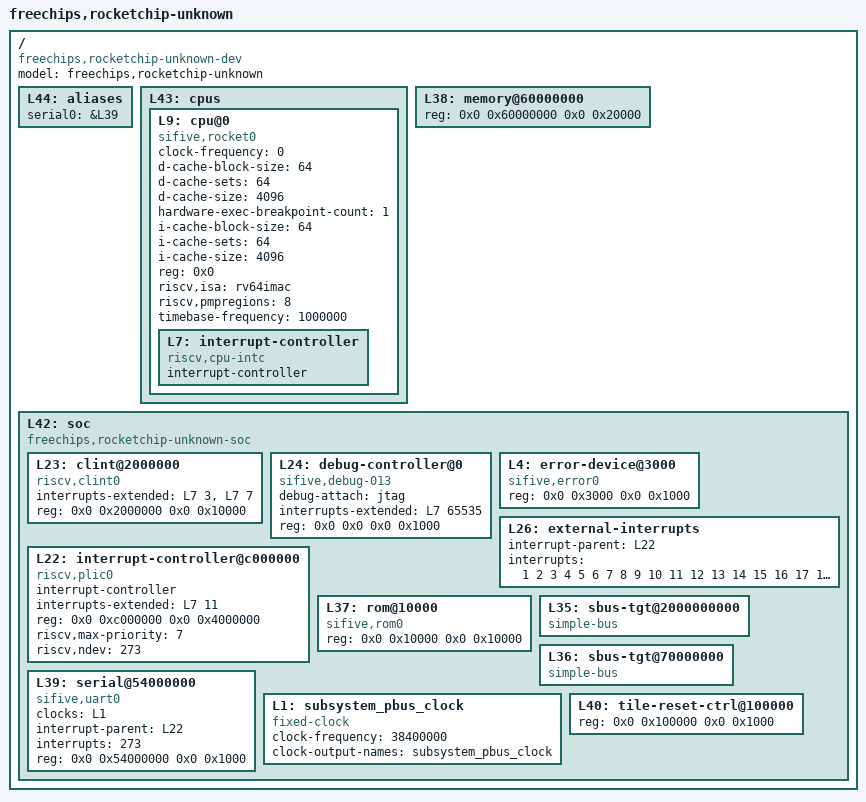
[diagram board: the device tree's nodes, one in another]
/dts-v1/;

/ {
    #address-cells = <2>;
    #size-cells = <2>;
    compatible = "freechips,rocketchip-unknown-dev";
    model = "freechips,rocketchip-unknown";
    L44: aliases {
        serial0 = &L39;
    };
    L43: cpus {
        #address-cells = <1>;
        #size-cells = <0>;
        L9: cpu@0 {
            clock-frequency = <0>;
            compatible = "sifive,rocket0", "riscv";
            d-cache-block-size = <64>;
            d-cache-sets = <64>;
            d-cache-size = <4096>;
            device_type = "cpu";
            hardware-exec-breakpoint-count = <1>;
            i-cache-block-size = <64>;
            i-cache-sets = <64>;
            i-cache-size = <4096>;
            reg = <0x0>;
            riscv,isa = "rv64imac";
            riscv,pmpregions = <8>;
            status = "okay";
            timebase-frequency = <1000000>;
            L7: interrupt-controller {
                #interrupt-cells = <1>;
                compatible = "riscv,cpu-intc";
                interrupt-controller;
            };
        };
    };
    L38: memory@60000000 {
        device_type = "memory";
        reg = <0x0 0x60000000 0x0 0x20000>;
    };
    L42: soc {
        #address-cells = <2>;
        #size-cells = <2>;
        compatible = "freechips,rocketchip-unknown-soc", "simple-bus";
        ranges;
        L23: clint@2000000 {
            compatible = "riscv,clint0";
            interrupts-extended = <&L7 3 &L7 7>;
            reg = <0x0 0x2000000 0x0 0x10000>;
            reg-names = "control";
        };
        L24: debug-controller@0 {
            compatible = "sifive,debug-013", "riscv,debug-013";
            debug-attach = "jtag";
            interrupts-extended = <&L7 65535>;
            reg = <0x0 0x0 0x0 0x1000>;
            reg-names = "control";
        };
        L4: error-device@3000 {
            compatible = "sifive,error0";
            reg = <0x0 0x3000 0x0 0x1000>;
        };
        L26: external-interrupts {
            interrupt-parent = <&L22>;
            interrupts = <1 2 3 4 5 6 7 8 9 10 11 12 13 14 15 16 17 18 19 20 21 22 23 24 25 26 27 28 29 30 31 32 33 34 35 36 37 38 39 40 41 42 43 44 45 46 47 48 49 50 51 52 53 54 55 56 57 58 59 60 61 62 63 64 65 66 67 68 69 70 71 72 73 74 75 76 77 78 79 80 81 82 83 84 85 86 87 88 89 90 91 92 93 94 95 96 97 98 99 100 101 102 103 104 105 106 107 108 109 110 111 112 113 114 115 116 117 118 119 120 121 122 123 124 125 126 127 128 129 130 131 132 133 134 135 136 137 138 139 140 141 142 143 144 145 146 147 148 149 150 151 152 153 154 155 156 157 158 159 160 161 162 163 164 165 166 167 168 169 170 171 172 173 174 175 176 177 178 179 180 181 182 183 184 185 186 187 188 189 190 191 192 193 194 195 196 197 198 199 200 201 202 203 204 205 206 207 208 209 210 211 212 213 214 215 216 217 218 219 220 221 222 223 224 225 226 227 228 229 230 231 232 233 234 235 236 237 238 239 240 241 242 243 244 245 246 247 248 249 250 251 252 253 254 255 256 257 258 259 260 261 262 263 264 265 266 267 268 269 270 271 272>;
        };
        L22: interrupt-controller@c000000 {
            #interrupt-cells = <1>;
            compatible = "riscv,plic0";
            interrupt-controller;
            interrupts-extended = <&L7 11>;
            reg = <0x0 0xc000000 0x0 0x4000000>;
            reg-names = "control";
            riscv,max-priority = <7>;
            riscv,ndev = <273>;
        };
        L37: rom@10000 {
            compatible = "sifive,rom0";
            reg = <0x0 0x10000 0x0 0x10000>;
            reg-names = "mem";
        };
        L35: sbus-tgt@2000000000 {
            #address-cells = <2>;
            #size-cells = <2>;
            compatible = "simple-bus";
            ranges = <0x20 0x0 0x20 0x0 0x30 0x0>;
        };
        L36: sbus-tgt@70000000 {
            #address-cells = <2>;
            #size-cells = <2>;
            compatible = "simple-bus";
            ranges = <0x0 0x70000000 0x0 0x70000000 0xf 0x90000000>;
        };
        L39: serial@54000000 {
            clocks = <&L1>;
            compatible = "sifive,uart0";
            interrupt-parent = <&L22>;
            interrupts = <273>;
            reg = <0x0 0x54000000 0x0 0x1000>;
            reg-names = "control";
        };
        L1: subsystem_pbus_clock {
            #clock-cells = <0>;
            clock-frequency = <38400000>;
            clock-output-names = "subsystem_pbus_clock";
            compatible = "fixed-clock";
        };
        L40: tile-reset-ctrl@100000 {
            reg = <0x0 0x100000 0x0 0x1000>;
            reg-names = "control";
        };
    };
};
